# DS_CM3 register map
Vendor: ARM Ltd.; Series: ARM Cortex M3; File version: 1.0
CPU: CM3 r2p1, little endian, MPU, no FPU, 3 interrupt priority bits
Registers are 32-bit, read-write, reset 0x0 unless marked. A register's access mark holds for its fields unless they carry their own. Offsets are from the block's base; [hi:lo] are bit positions; {n}, {i} and the like mark numbered series.

## UART0
Base 0x40004000
Same registers: UART1 0x40005000, UART2 0x4002C000, UART3 0x4002D000, UART4 0x4002E000
0x00 DATA — Recieve and Transmit Data Value
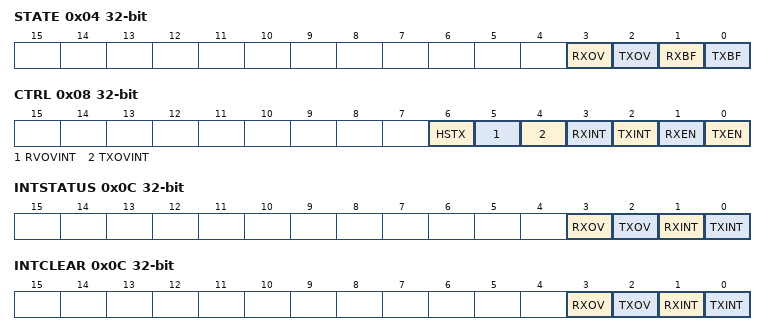
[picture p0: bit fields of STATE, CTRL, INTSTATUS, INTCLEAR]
0x04 STATE — UART Status Register
  [3] RXOV write-1-clears — RX Buffer Overun (write 1 to clear)
  [2] TXOV write-1-clears — TX Buffer Overun (write 1 to clear)
  [1] RXBF ro — RX Buffer Full
  [0] TXBF ro — TX Buffer Full
0x08 CTRL — UART Control Register
  [all] fields
    0=Disabled; 1=Enabled
  [6] HSTX — High Speed Test Mode for TX only
  [5] RVOVINT — RX Overrun Interrupt Enable
  [4] TXOVINT — TX Overrun Interrupt Enable
  [3] RXINT — RX Interrupt Enable
  [2] TXINT — TX Interrupt Enable
  [1] RXEN — RX Enable
  [0] TXEN — TX Enable
0x0C INTSTATUS ro — UART Interrupt Status Register
  [3] RXOV — RX Overrun interrupt
  [2] TXOV — TX Overrun interrupt
  [1] RXINT — RX interrupt
  [0] TXINT — TX interrupt
0x0C INTCLEAR wo (alternate view of INTSTATUS) — UART Interrupt CLEAR Register
  [3] RXOV write-1-clears — RX Overrun interrupt
  [2] TXOV write-1-clears — TX Overrun interrupt
  [1] RXINT write-1-clears — RX interrupt
  [0] TXINT write-1-clears — TX interrupt
0x10 BAUDDIV — Baudrate Divider

## RTC — Real Time Clock (PL031)
Base 0x40006000
0x00 DR ro — Data register
0x04 MR — Match register
0x08 LR — Load register
0x0C CR — Control register
0x10 IMSC — Interrupt mask set and clear register
0x14 RIS ro — Raw interrupt status register
0x18 MIS ro — Masked interrupt status register
0x1C ICR wo write-1-clears — Interrupt clear register

## WATCHDOG — Watchdog Timer
Base 0x40008000
0x00 LOAD
0x04 VALUE ro
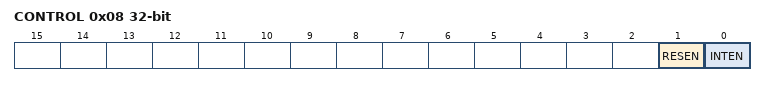
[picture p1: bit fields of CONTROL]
0x08 CONTROL
  [1] RESEN — Watchdog reset output enable
    0=Disable Watchdog reset; 1=ENable Watchdog reset
  [0] INTEN — Interrupt event enable
    0=Disable Watchdog interrupt; 1=Enable Watchdog interrupt
0x0C INTCLR wo — Interrupt Clear Register
  [0] INT write-1-clears — Interrupt
0x10 RIS ro — Raw Interrupt Status Register
  [0] RIS — Raw watchdog interrupt
0x14 MIS ro — Mask Interrupt Status Register
  [0] MIS — Masked Watchdog interrupt
0xC00 LOCK

## TRNG — True Random Number Generator
Base 0x4000F000
0x100 RNG_IMR — Interrupt Masking Register
0x104 ISR ro — Interrupt Status Register
0x108 ICR wo — Interrupt status bit Clear Register
0x10C CONFIG — TRNG Configuration Register
0x110 VALID ro — TRNG Valid register
{0x114+4i} EHR_DATA[{i}] (i=0..5) ro
0x12C RND_SOURCE_ENABLE — Random Source Enable registe
0x130 SAMPLE_CNT1 — Sample Counter register
0x134 AUTOCORR_STATISTIC — Autocorrelation Statistic register
0x138 DEBUG_CONTROL ro — TRNG Debug Control register
0x140 SW_RESET wo — TRNG Software Reset Register
0x1B8 BUSY ro — TRNG Busy status register
0x1BC RST_BITS_COUNTER wo — Reset Bits Counter register
{0x1E0+4i} RST_BIST_COUNTER[{i}] (i=0..2) — RNG BIST Counter register

## GPIO0 — general-purpose I/O
Base 0x40010000
Same registers: GPIO1 0x40011000, GPIO2 0x40012000, GPIO3 0x40013000, GPIO4 0x40030000, GPIO5 0x40031000
0x00 DATA
0x04 DATAOUT — Data Output Register
0x10 OUTENSET — Ouptut enable set Register
0x14 OUTENCLR — Ouptut enable clear Register
0x18 ALTFUNCSET — Alternate function set Register
0x1C ALTFUNCCLR — Alternate function clear Register
0x20 INTENSET — Interrupt enable set Register
0x24 INTENCLR — Interrupt enable clear Register
0x28 INTTYPESET — Interrupt type set Register
0x2C INTTYPECLR — Interrupt type clear Register
0x30 INTPOLSET — Polarity-level, edge interrupt configuration set Register
0x34 INTPOLCLR — Polarity-level, edge interrupt configuration clear Register
0x38 INTSTATUS ro — Interrupt Status Register
0x38 INTCLEAR wo write-1-clears (alternate view of INTSTATUS) — Interrupt CLEAR Register
